# MM32F103xx register map
File version: 1.3
Registers are 32-bit, read-write, reset 0x0 unless marked. A register's access mark holds for its fields unless they carry their own. Offsets are from the block's base; [hi:lo] are bit positions; {n}, {i} and the like mark numbered series.

## PWR — Power control
Base 0x40007000
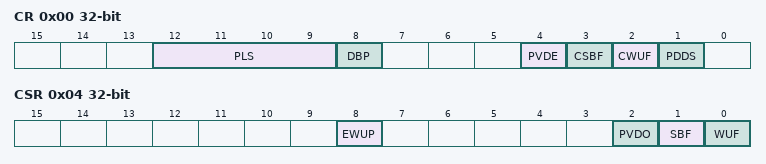
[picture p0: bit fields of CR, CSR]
0x00 CR
  [12:9] PLS — PVD level selection
  [8] DBP — domain write protection
  [4] PVDE — Power voltage detector enable
  [3] CSBF — Clear standby flag
  [2] CWUF — Clear wakeup flag
  [1] PDDS — Power down deepsleep
0x04 CSR
  [8] EWUP — Enable WKUP pin
  [2] PVDO — PVD output
  [1] SBF — Standby flag
  [0] WUF — Wakeup flag

## CAN — Controller area network
Base 0x40006400
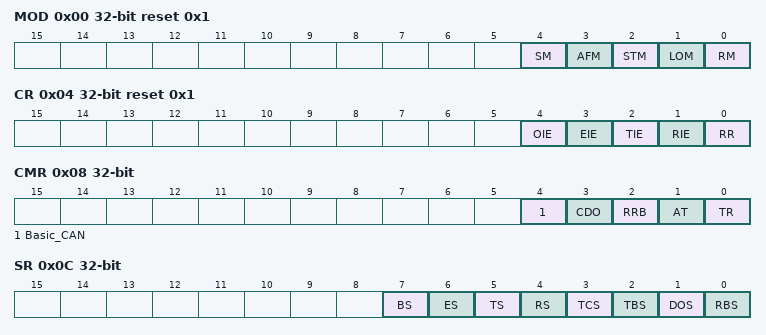
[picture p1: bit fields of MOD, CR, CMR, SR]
0x00 MOD reset 0x1
  [4] SM — Sleep mode
  [3] AFM — Acceptance filter mode
  [2] STM — Self test mode
  [1] LOM — Listen only mode
  [0] RM — Reset mode
0x04 CR reset 0x1
  [4] OIE — Overflow interrupt enable
  [3] EIE — Error interrupt enable
  [2] TIE — Transmit interrupt enable
  [1] RIE — Receive interrupt enable
  [0] RR — Reset request
0x08 CMR
  [4] Basic_CAN
  [3] CDO — Clear data overrun
  [2] RRB — Release receive buffer
  [1] AT — Abort transmission
  [0] TR — Transmission request
0x0C SR
  [7] BS — Bus status
  [6] ES — Error status
  [5] TS — Transmit status
  [4] RS — Receive status
  [3] TCS — Transmission complete status
  [2] TBS — Transmit buffer status
  [1] DOS — Data overrun status
  [0] RBS — Receive buffer status
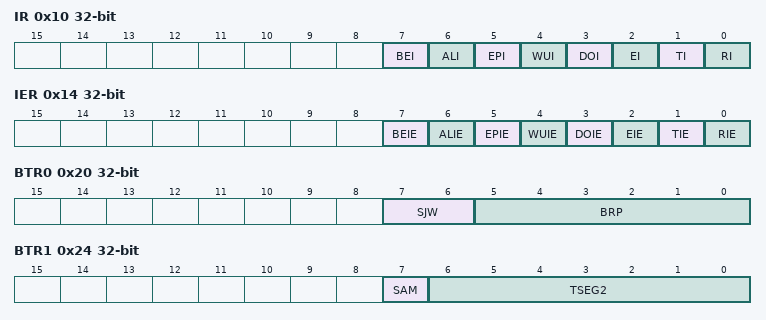
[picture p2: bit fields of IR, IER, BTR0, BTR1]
0x10 IR ro
  [7] BEI
  [6] ALI
  [5] EPI
  [4] WUI — Wake-up interrupt
  [3] DOI — Data overrun interrupt
  [2] EI — Error interrupt
  [1] TI — Transmit interrupt
  [0] RI — Receive interrupt
0x14 IER
  [7] BEIE — Bus error interrupt enable
  [6] ALIE — Arbitration lost interrupt enable
  [5] EPIE — Error passive interrupt enable
  [4] WUIE — Wake up interrupt enable
  [3] DOIE — Data overrun interrupt enable
  [2] EIE — Error interrupt enable
  [1] TIE — Transmit interrupt enable
  [0] RIE — Receive interrupt enable
0x18 ACR
  [7:0] AC — Acceptance code
0x1C AOS — ACM
  [7:0] AM — Acceptance mask
0x20 BTR0
  [7:6] SJW — Synchronization jump width
  [5:0] BRP — Baud rate prescaler
0x24 BTR1
  [7] SAM — Sampling
  [6:0] TSEG2 — Time segment 2
0x28 TXID0
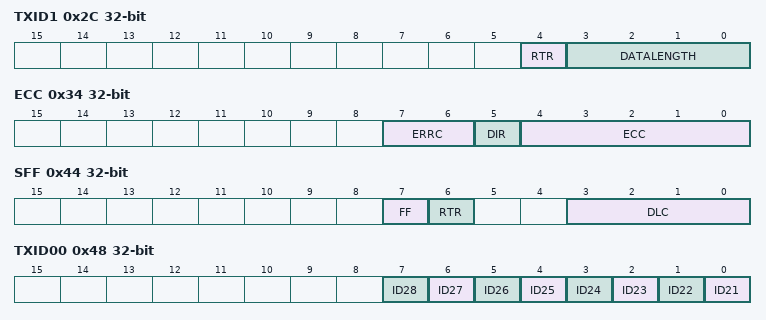
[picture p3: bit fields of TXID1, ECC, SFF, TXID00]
0x2C TXID1
  [4] RTR — Remote transmission request
  [3:0] DATALENGTH — Data length code 0~8
0x30 ALC
  [4:0] BITNO — Bit number
0x34 ECC ro
  [7:6] ERRC — Error code
  [5] DIR — Direction
  [4:0] ECC — Error code capture
0x38 EWLR reset 0x96
  [7:0] EWL — Programmable error warning limit
0x3C RXERR
  [7:0] RXERR — RX error counter register
0x40 TXERR
  [7:0] TXERR — TX error counter register
0x44 SFF
  [7] FF — Frame format
  [6] RTR — Remote transmission request
  [3:0] DLC — Data length code bit
0x48 TXID00
  [n-21] ID{n} (n=21..28) — Identifier bit {n}
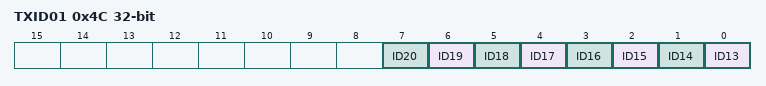
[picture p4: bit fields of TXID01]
0x4C TXID01
  [n-13] ID{n} (n=13..20) — Identifier bit {n}
0x50 TXDATA0
  [7:0] DATA0
0x54 TXDATA1
  [7:0] DATA1
0x58 CDR
  [7] MODE — CAN mode

## GPIOA — General purpose I/O
Base 0x40010800
Same registers: GPIOB 0x40010C00, GPIOC 0x40011000, GPIOD 0x40011400, GPIOE 0x40011800
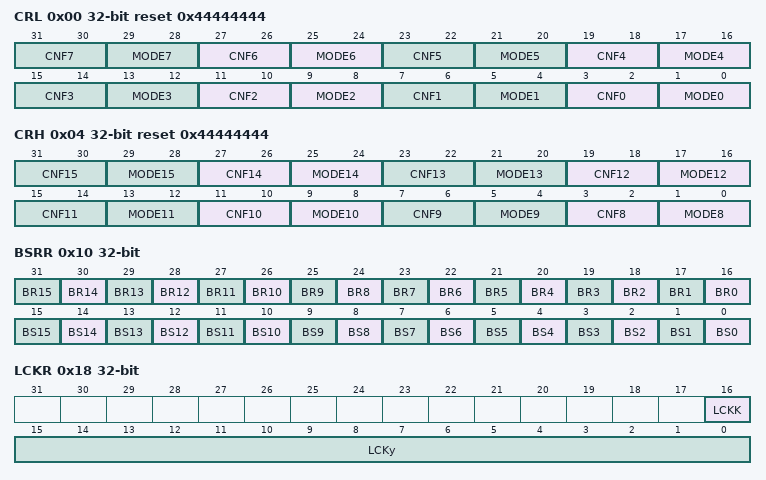
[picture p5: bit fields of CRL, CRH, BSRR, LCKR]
0x00 CRL reset 0x44444444
  [4n+3:4n+2] CNF{n} (n=0..7) — Port {n} configuration bits
  [4n+1:4n] MODE{n} (n=0..7) — Port {n} mode bits
0x04 CRH reset 0x44444444
  [4n-29:4n-30] CNF{n} (n=8..15) — Port {n} configuration bits
  [4n-31:4n-32] MODE{n} (n=8..15) — Port {n} mode bits
0x08 IDR ro
  [15:0] IDRy — Port input data
0x0C ODR
  [15:0] ODRy — Port output data
0x10 BSRR wo
  [n+16] BR{n} (n=0..15) — Port A Reset bit {n}
  [n] BS{n} (n=0..15) — Port A Set bit {n}
0x14 BRR wo
  [15:0] BRy — Port A Reset bit y
0x18 LCKR
  [16] LCKK — Lock key
  [15:0] LCKy — Port A Lock bit y

## AFIO — Alternate function I/O
Base 0x40010000
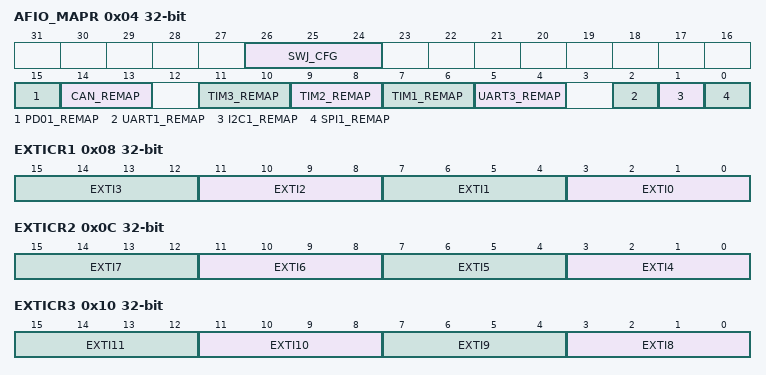
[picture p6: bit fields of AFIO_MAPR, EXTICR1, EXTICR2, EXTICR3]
0x04 AFIO_MAPR
  [26:24] SWJ_CFG — Serial wire JTAG configuration
  [15] PD01_REMAP — Port D0/Port D1 mapping on OSC_IN/OSC_OUT
  [14:13] CAN_REMAP — CAN alternate function remapping
  [11:10] TIM3_REMAP — TIM3 remapping
  [9:8] TIM2_REMAP — TIM2 remapping
  [7:6] TIM1_REMAP — TIM1 remapping
  [5:4] UART3_REMAP — UART 3 remapping
  [2] UART1_REMAP — UART 1 remapping
  [1] I2C1_REMAP — I2C 1 remapping
  [0] SPI1_REMAP — SPI 1 remapping
0x08 EXTICR1
  [4n+3:4n] EXTI{n} (n=0..3) — EXTI{n} configuration
0x0C EXTICR2
  [4n-13:4n-16] EXTI{n} (n=4..7) — EXTI{n} configuration
0x10 EXTICR3
  [4n-29:4n-32] EXTI{n} (n=8..11) — EXTI{n} configuration
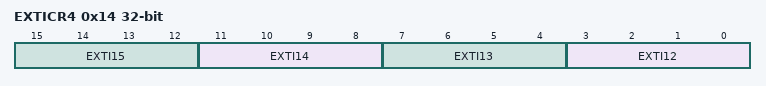
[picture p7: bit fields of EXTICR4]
0x14 EXTICR4
  [4n-45:4n-48] EXTI{n} (n=12..15) — EXTI{n} configuration
